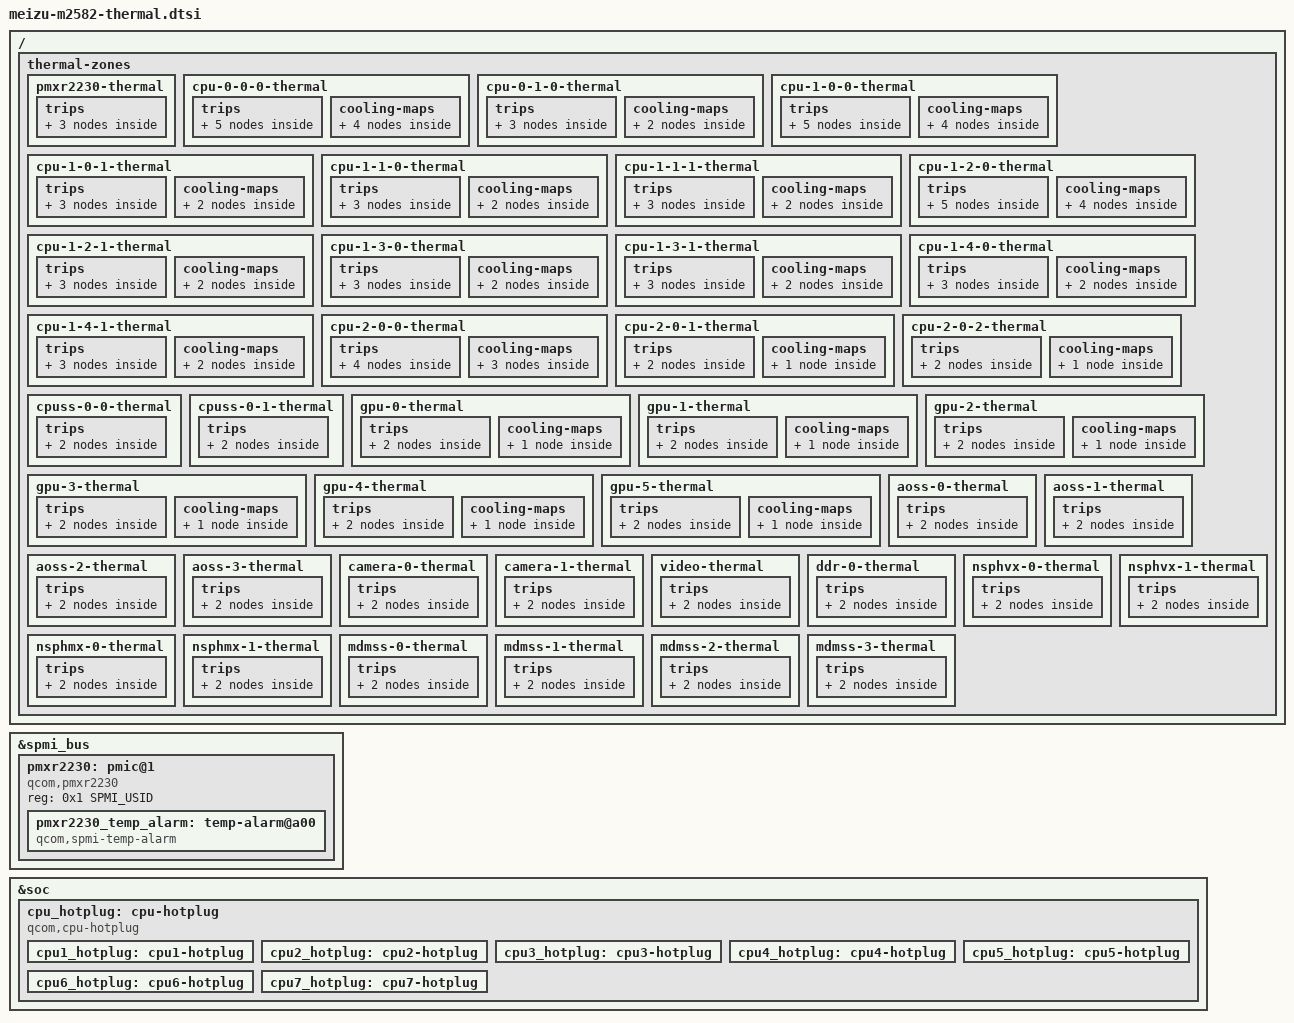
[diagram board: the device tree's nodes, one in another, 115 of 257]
// SPDX-License-Identifier: BSD-3-Clause
#include <dt-bindings/thermal/thermal.h>
/*
 * Meizu 22 (M2582) -- thermal zones.
 *
 * Two independent sensor families.  The TSENS zones are the ones with
 * actuators -- the three cpufreq cooling devices and the GPU's devfreq
 * cooling device:
 *
 *  - SoC TSENS (nodes in tuna.dtsi), which is uncalibrated on this part: the
 *    result register reports deci-Celsius and the vendor's tree claims no
 *    calibration cells, so the generic v2 path is what the phone itself runs.
 *    All 39 sensors are zones, as the vendor has them.
 *
 *  - The PMXR2230, which supplies the CPU rails and protects its own die in
 *    hardware: stage 2 and stage 3 shutdown are armed by default, so it cuts
 *    the rails with Linux out of the loop.  Its zone is a stage indicator
 *    rather than a thermometer, and it cannot drive a cooling device on this
 *    kernel -- see the note in that zone.
 *
 * Actuators: cpufreq-cpu0/-cpu4/-cpu7 for the clusters, devfreq-3d00000.gpu
 * for the GPU, and cpuN-hotplug for the emergency trips.  The board
 * thermistors are not modelled yet, so the vendor's skin-driven ladder has no
 * equivalent here.
 */
&spmi_bus {
	pmxr2230: pmic@1 {
		compatible = "qcom,pmxr2230", "qcom,spmi-pmic";
		reg = <0x1 SPMI_USID>;
		#address-cells = <1>;
		#size-cells = <0>;

		pmxr2230_temp_alarm: temp-alarm@a00 {
			compatible = "qcom,spmi-temp-alarm";
			reg = <0xa00>;
			interrupts = <0x1 0xa 0x0 IRQ_TYPE_EDGE_BOTH>;
			#thermal-sensor-cells = <0>;
		};
	};
};

/ {
	thermal-zones {
		pmxr2230-thermal {
			polling-delay-passive = <100>;

			thermal-sensors = <&pmxr2230_temp_alarm>;

			trips {
				pmxr2230_trip0: trip0 {
					temperature = <95000>;
					hysteresis = <0>;
					type = "passive";
				};

				pmxr2230_trip1: trip1 {
					temperature = <115000>;
					hysteresis = <0>;
					type = "hot";
				};

				pmxr2230_trip2: trip2 {
					temperature = <145000>;
					hysteresis = <0>;
					type = "critical";
				};
			};

			/*
			 * No cooling map: it cannot bind.  thermal_of.c matches a map
			 * to a trip through trip->priv, but qcom-spmi-temp-alarm stores
			 * its own trip index there (THERMAL_INT_TO_TRIP_PRIV, a core
			 * sanctioned encoding), so every lookup compares a trip node
			 * against a small integer.  Fixing that is a thermal core change.
			 * The zone is also not a thermometer: it reports DEFAULT_TEMP
			 * (37 C) until the PMIC enters a hardware stage.  Stage 2/3
			 * shutdown still protects the board on its own.
			 */
		};

		/*
		 * CPU sensors, all 17 of them, as the vendor models them.
		 *
		 *   tsens0  s1..s3 cpu-2-0-{0,1,2}   s4,s5 cpu-1-0-{0,1}
		 *           s6,s7 cpu-1-1-{0,1}      s0    aoss-0
		 *   tsens1  s1,s2 cpuss-0-{0,1}      s3,s4 cpu-1-2-{0,1}
		 *           s5,s6 cpu-1-3-{0,1}      s7,s8 cpu-1-4-{0,1}
		 *           s9    cpu-0-0-0          s10   cpu-0-1-0        s0 aoss-1
		 *
		 * The five cluster hotspots carry the graded ladder (85 C caps the
		 * clusters four OPPs down, 95 C may use the whole table).  The other
		 * twelve only carry the emergency trips: fourteen more copies of the
		 * ladder would give any single sensor the power to throttle the SoC.
		 *
		 * Emergency, per zone, following the vendor's zone-to-CPU mapping:
		 * 118 C offline that CPU, 120 C offline its policy peers, 125 C
		 * critical.  The cooling spec is <&cpuN_hotplug 0 1>, deliberately
		 * not the vendor's 1 1: step_wise releases to an instance's lower
		 * bound, so 1 1 latches the CPU offline for good.  Zones the vendor
		 * points at cpu0 use its policy sibling, which the kernel can
		 * actually offline.
		 */
		cpu-0-0-0-thermal {
			polling-delay-passive = <100>;
			thermal-sensors = <&tsens1 9>;
			trips {
				cpu_0_0_0_warm: trip-point0 {
					temperature = <85000>;
					hysteresis = <2000>;
					type = "passive";
				};
				cpu_0_0_0_alert: trip-point1 {
					temperature = <95000>;
					hysteresis = <2000>;
					type = "passive";
				};
				cpu_0_0_0_emerg: trip-point2 {
					temperature = <118000>;
					hysteresis = <8000>;
					type = "passive";
				};
				cpu_0_0_0_emerg2: trip-point3 {
					temperature = <120000>;
					hysteresis = <10000>;
					type = "passive";
				};
				cpu_0_0_0_crit: trip-point4 {
					temperature = <125000>;
					hysteresis = <1000>;
					type = "critical";
				};
			};
			cooling-maps {
				map-warm {
					trip = <&cpu_0_0_0_warm>;
					cooling-device = <&cpu0 0 4>, <&cpu4 0 4>, <&cpu7 0 4>;
				};
				map-hot {
					trip = <&cpu_0_0_0_alert>;
					cooling-device = <&cpu0 THERMAL_NO_LIMIT THERMAL_NO_LIMIT>,
							 <&cpu4 THERMAL_NO_LIMIT THERMAL_NO_LIMIT>,
							 <&cpu7 THERMAL_NO_LIMIT THERMAL_NO_LIMIT>;
				};
				map-emerg {
					trip = <&cpu_0_0_0_emerg>;
					cooling-device = <&cpu1_hotplug 0 1>;
				};
				map-emerg2 {
					trip = <&cpu_0_0_0_emerg2>;
					cooling-device = <&cpu2_hotplug 0 1>,
							 <&cpu3_hotplug 0 1>;
				};
			};
		};

		cpu-0-1-0-thermal {
			polling-delay-passive = <100>;
			thermal-sensors = <&tsens1 10>;
			trips {
				cpu_0_1_0_emerg: trip-point2 {
					temperature = <118000>;
					hysteresis = <8000>;
					type = "passive";
				};
				cpu_0_1_0_emerg2: trip-point3 {
					temperature = <120000>;
					hysteresis = <10000>;
					type = "passive";
				};
				cpu_0_1_0_crit: trip-point4 {
					temperature = <125000>;
					hysteresis = <1000>;
					type = "critical";
				};
			};
			cooling-maps {
				map-emerg {
					trip = <&cpu_0_1_0_emerg>;
					cooling-device = <&cpu1_hotplug 0 1>;
				};
				map-emerg2 {
					trip = <&cpu_0_1_0_emerg2>;
					cooling-device = <&cpu2_hotplug 0 1>,
							 <&cpu3_hotplug 0 1>;
				};
			};
		};

		cpu-1-0-0-thermal {
			polling-delay-passive = <100>;
			thermal-sensors = <&tsens0 4>;
			trips {
				cpu_1_0_0_warm: trip-point0 {
					temperature = <85000>;
					hysteresis = <2000>;
					type = "passive";
				};
				cpu_1_0_0_alert: trip-point1 {
					temperature = <95000>;
					hysteresis = <2000>;
					type = "passive";
				};
				cpu_1_0_0_emerg: trip-point2 {
					temperature = <118000>;
					hysteresis = <8000>;
					type = "passive";
				};
				cpu_1_0_0_emerg2: trip-point3 {
					temperature = <120000>;
					hysteresis = <10000>;
					type = "passive";
				};
				cpu_1_0_0_crit: trip-point4 {
					temperature = <125000>;
					hysteresis = <1000>;
					type = "critical";
				};
			};
			cooling-maps {
				map-warm {
					trip = <&cpu_1_0_0_warm>;
					cooling-device = <&cpu0 0 4>, <&cpu4 0 4>, <&cpu7 0 4>;
				};
				map-hot {
					trip = <&cpu_1_0_0_alert>;
					cooling-device = <&cpu0 THERMAL_NO_LIMIT THERMAL_NO_LIMIT>,
							 <&cpu4 THERMAL_NO_LIMIT THERMAL_NO_LIMIT>,
							 <&cpu7 THERMAL_NO_LIMIT THERMAL_NO_LIMIT>;
				};
				map-emerg {
					trip = <&cpu_1_0_0_emerg>;
					cooling-device = <&cpu5_hotplug 0 1>;
				};
				map-emerg2 {
					trip = <&cpu_1_0_0_emerg2>;
					cooling-device = <&cpu4_hotplug 0 1>,
							 <&cpu6_hotplug 0 1>;
				};
			};
		};

		cpu-1-0-1-thermal {
			polling-delay-passive = <100>;
			thermal-sensors = <&tsens0 5>;
			trips {
				cpu_1_0_1_emerg: trip-point2 {
					temperature = <118000>;
					hysteresis = <8000>;
					type = "passive";
				};
				cpu_1_0_1_emerg2: trip-point3 {
					temperature = <120000>;
					hysteresis = <10000>;
					type = "passive";
				};
				cpu_1_0_1_crit: trip-point4 {
					temperature = <125000>;
					hysteresis = <1000>;
					type = "critical";
				};
			};
			cooling-maps {
				map-emerg {
					trip = <&cpu_1_0_1_emerg>;
					cooling-device = <&cpu5_hotplug 0 1>;
				};
				map-emerg2 {
					trip = <&cpu_1_0_1_emerg2>;
					cooling-device = <&cpu4_hotplug 0 1>,
							 <&cpu6_hotplug 0 1>;
				};
			};
		};

		cpu-1-1-0-thermal {
			polling-delay-passive = <100>;
			thermal-sensors = <&tsens0 6>;
			trips {
				cpu_1_1_0_emerg: trip-point2 {
					temperature = <118000>;
					hysteresis = <8000>;
					type = "passive";
				};
				cpu_1_1_0_emerg2: trip-point3 {
					temperature = <120000>;
					hysteresis = <10000>;
					type = "passive";
				};
				cpu_1_1_0_crit: trip-point4 {
					temperature = <125000>;
					hysteresis = <1000>;
					type = "critical";
				};
			};
			cooling-maps {
				map-emerg {
					trip = <&cpu_1_1_0_emerg>;
					cooling-device = <&cpu6_hotplug 0 1>;
				};
				map-emerg2 {
					trip = <&cpu_1_1_0_emerg2>;
					cooling-device = <&cpu4_hotplug 0 1>,
							 <&cpu5_hotplug 0 1>;
				};
			};
		};

		cpu-1-1-1-thermal {
			polling-delay-passive = <100>;
			thermal-sensors = <&tsens0 7>;
			trips {
				cpu_1_1_1_emerg: trip-point2 {
					temperature = <118000>;
					hysteresis = <8000>;
					type = "passive";
				};
				cpu_1_1_1_emerg2: trip-point3 {
					temperature = <120000>;
					hysteresis = <10000>;
					type = "passive";
				};
				cpu_1_1_1_crit: trip-point4 {
					temperature = <125000>;
					hysteresis = <1000>;
					type = "critical";
				};
			};
			cooling-maps {
				map-emerg {
					trip = <&cpu_1_1_1_emerg>;
					cooling-device = <&cpu6_hotplug 0 1>;
				};
				map-emerg2 {
					trip = <&cpu_1_1_1_emerg2>;
					cooling-device = <&cpu4_hotplug 0 1>,
							 <&cpu5_hotplug 0 1>;
				};
			};
		};

		cpu-1-2-0-thermal {
			polling-delay-passive = <100>;
			thermal-sensors = <&tsens1 3>;
			trips {
				cpu_1_2_0_warm: trip-point0 {
					temperature = <85000>;
					hysteresis = <2000>;
					type = "passive";
				};
				cpu_1_2_0_alert: trip-point1 {
					temperature = <95000>;
					hysteresis = <2000>;
					type = "passive";
				};
				cpu_1_2_0_emerg: trip-point2 {
					temperature = <118000>;
					hysteresis = <8000>;
					type = "passive";
				};
				cpu_1_2_0_emerg2: trip-point3 {
					temperature = <120000>;
					hysteresis = <10000>;
					type = "passive";
				};
				cpu_1_2_0_crit: trip-point4 {
					temperature = <125000>;
					hysteresis = <1000>;
					type = "critical";
				};
			};
			cooling-maps {
				map-warm {
					trip = <&cpu_1_2_0_warm>;
					cooling-device = <&cpu0 0 4>, <&cpu4 0 4>, <&cpu7 0 4>;
				};
				map-hot {
					trip = <&cpu_1_2_0_alert>;
					cooling-device = <&cpu0 THERMAL_NO_LIMIT THERMAL_NO_LIMIT>,
							 <&cpu4 THERMAL_NO_LIMIT THERMAL_NO_LIMIT>,
							 <&cpu7 THERMAL_NO_LIMIT THERMAL_NO_LIMIT>;
				};
				map-emerg {
					trip = <&cpu_1_2_0_emerg>;
					cooling-device = <&cpu2_hotplug 0 1>;
				};
				map-emerg2 {
					trip = <&cpu_1_2_0_emerg2>;
					cooling-device = <&cpu1_hotplug 0 1>,
							 <&cpu3_hotplug 0 1>;
				};
			};
		};

		cpu-1-2-1-thermal {
			polling-delay-passive = <100>;
			thermal-sensors = <&tsens1 4>;
			trips {
				cpu_1_2_1_emerg: trip-point2 {
					temperature = <118000>;
					hysteresis = <8000>;
					type = "passive";
				};
				cpu_1_2_1_emerg2: trip-point3 {
					temperature = <120000>;
					hysteresis = <10000>;
					type = "passive";
				};
				cpu_1_2_1_crit: trip-point4 {
					temperature = <125000>;
					hysteresis = <1000>;
					type = "critical";
				};
			};
			cooling-maps {
				map-emerg {
					trip = <&cpu_1_2_1_emerg>;
					cooling-device = <&cpu2_hotplug 0 1>;
				};
				map-emerg2 {
					trip = <&cpu_1_2_1_emerg2>;
					cooling-device = <&cpu1_hotplug 0 1>,
							 <&cpu3_hotplug 0 1>;
				};
			};
		};

		cpu-1-3-0-thermal {
			polling-delay-passive = <100>;
			thermal-sensors = <&tsens1 5>;
			trips {
				cpu_1_3_0_emerg: trip-point2 {
					temperature = <118000>;
					hysteresis = <8000>;
					type = "passive";
				};
				cpu_1_3_0_emerg2: trip-point3 {
					temperature = <120000>;
					hysteresis = <10000>;
					type = "passive";
				};
				cpu_1_3_0_crit: trip-point4 {
					temperature = <125000>;
					hysteresis = <1000>;
					type = "critical";
				};
			};
			cooling-maps {
				map-emerg {
					trip = <&cpu_1_3_0_emerg>;
					cooling-device = <&cpu3_hotplug 0 1>;
				};
				map-emerg2 {
					trip = <&cpu_1_3_0_emerg2>;
					cooling-device = <&cpu1_hotplug 0 1>,
							 <&cpu2_hotplug 0 1>;
				};
			};
		};

		cpu-1-3-1-thermal {
			polling-delay-passive = <100>;
			thermal-sensors = <&tsens1 6>;
			trips {
				cpu_1_3_1_emerg: trip-point2 {
					temperature = <118000>;
					hysteresis = <8000>;
					type = "passive";
				};
				cpu_1_3_1_emerg2: trip-point3 {
					temperature = <120000>;
					hysteresis = <10000>;
					type = "passive";
				};
				cpu_1_3_1_crit: trip-point4 {
					temperature = <125000>;
					hysteresis = <1000>;
					type = "critical";
				};
			};
			cooling-maps {
				map-emerg {
					trip = <&cpu_1_3_1_emerg>;
					cooling-device = <&cpu3_hotplug 0 1>;
				};
				map-emerg2 {
					trip = <&cpu_1_3_1_emerg2>;
					cooling-device = <&cpu1_hotplug 0 1>,
							 <&cpu2_hotplug 0 1>;
				};
			};
		};

		cpu-1-4-0-thermal {
			polling-delay-passive = <100>;
			thermal-sensors = <&tsens1 7>;
			trips {
				cpu_1_4_0_emerg: trip-point2 {
					temperature = <118000>;
					hysteresis = <8000>;
					type = "passive";
				};
				cpu_1_4_0_emerg2: trip-point3 {
					temperature = <120000>;
					hysteresis = <10000>;
					type = "passive";
				};
				cpu_1_4_0_crit: trip-point4 {
					temperature = <125000>;
					hysteresis = <1000>;
					type = "critical";
				};
			};
			cooling-maps {
				map-emerg {
					trip = <&cpu_1_4_0_emerg>;
					cooling-device = <&cpu4_hotplug 0 1>;
				};
				map-emerg2 {
					trip = <&cpu_1_4_0_emerg2>;
					cooling-device = <&cpu5_hotplug 0 1>,
							 <&cpu6_hotplug 0 1>;
				};
			};
		};

		cpu-1-4-1-thermal {
			polling-delay-passive = <100>;
			thermal-sensors = <&tsens1 8>;
			trips {
				cpu_1_4_1_emerg: trip-point2 {
					temperature = <118000>;
					hysteresis = <8000>;
					type = "passive";
				};
				cpu_1_4_1_emerg2: trip-point3 {
					temperature = <120000>;
					hysteresis = <10000>;
					type = "passive";
				};
				cpu_1_4_1_crit: trip-point4 {
					temperature = <125000>;
					hysteresis = <1000>;
					type = "critical";
				};
			};
			cooling-maps {
				map-emerg {
					trip = <&cpu_1_4_1_emerg>;
					cooling-device = <&cpu4_hotplug 0 1>;
				};
				map-emerg2 {
					trip = <&cpu_1_4_1_emerg2>;
					cooling-device = <&cpu5_hotplug 0 1>,
							 <&cpu6_hotplug 0 1>;
				};
			};
		};

		cpu-2-0-0-thermal {
			polling-delay-passive = <100>;
			thermal-sensors = <&tsens0 1>;
			trips {
				cpu_2_0_0_warm: trip-point0 {
					temperature = <85000>;
					hysteresis = <2000>;
					type = "passive";
				};
				cpu_2_0_0_alert: trip-point1 {
					temperature = <95000>;
					hysteresis = <2000>;
					type = "passive";
				};
				cpu_2_0_0_emerg: trip-point2 {
					temperature = <118000>;
					hysteresis = <8000>;
					type = "passive";
				};
				cpu_2_0_0_crit: trip-point4 {
					temperature = <125000>;
					hysteresis = <1000>;
					type = "critical";
				};
			};
			cooling-maps {
				map-warm {
					trip = <&cpu_2_0_0_warm>;
					cooling-device = <&cpu0 0 4>, <&cpu4 0 4>, <&cpu7 0 4>;
				};
				map-hot {
					trip = <&cpu_2_0_0_alert>;
					cooling-device = <&cpu0 THERMAL_NO_LIMIT THERMAL_NO_LIMIT>,
							 <&cpu4 THERMAL_NO_LIMIT THERMAL_NO_LIMIT>,
							 <&cpu7 THERMAL_NO_LIMIT THERMAL_NO_LIMIT>;
				};
				map-emerg {
					trip = <&cpu_2_0_0_emerg>;
					cooling-device = <&cpu7_hotplug 0 1>;
				};
			};
		};

		cpu-2-0-1-thermal {
			polling-delay-passive = <100>;
			thermal-sensors = <&tsens0 2>;
			trips {
				cpu_2_0_1_emerg: trip-point2 {
					temperature = <118000>;
					hysteresis = <8000>;
					type = "passive";
				};
				cpu_2_0_1_crit: trip-point4 {
					temperature = <125000>;
					hysteresis = <1000>;
					type = "critical";
				};
			};
			cooling-maps {
				map-emerg {
					trip = <&cpu_2_0_1_emerg>;
					cooling-device = <&cpu7_hotplug 0 1>;
				};
			};
		};

		cpu-2-0-2-thermal {
			polling-delay-passive = <100>;
			thermal-sensors = <&tsens0 3>;
			trips {
				cpu_2_0_2_emerg: trip-point2 {
					temperature = <118000>;
					hysteresis = <8000>;
					type = "passive";
				};
				cpu_2_0_2_crit: trip-point4 {
					temperature = <125000>;
					hysteresis = <1000>;
					type = "critical";
				};
			};
			cooling-maps {
				map-emerg {
					trip = <&cpu_2_0_2_emerg>;
					cooling-device = <&cpu7_hotplug 0 1>;
				};
			};
		};

		cpuss-0-0-thermal {
			polling-delay-passive = <100>;
			thermal-sensors = <&tsens1 1>;
			trips {
				cpuss_0_0_alert: trip-point0 {
					temperature = <105000>;
					hysteresis = <5000>;
					type = "passive";
				};
				cpuss_0_0_crit: trip-point4 {
					temperature = <125000>;
					hysteresis = <1000>;
					type = "critical";
				};
			};
		};

		cpuss-0-1-thermal {
			polling-delay-passive = <100>;
			thermal-sensors = <&tsens1 2>;
			trips {
				cpuss_0_1_alert: trip-point0 {
					temperature = <105000>;
					hysteresis = <5000>;
					type = "passive";
				};
				cpuss_0_1_crit: trip-point4 {
					temperature = <125000>;
					hysteresis = <1000>;
					type = "critical";
				};
			};
		};

		/*
		 * GPU: six sensors (tsens2 s5..s10), as the vendor has them.  The
		 * vendor's own die controller runs off gpu-2, so a single zone was
		 * probably not the hot corner.  All six share one cooling device and
		 * __thermal_cdev_update() keeps the deepest request.
		 *
		 * 105 C with the whole OPP table, not the vendor's 0..2: it leaves the
		 * deep cap to its userspace policy at 45.5 C skin, and we have none.
		 */

		gpu-0-thermal {
			polling-delay-passive = <10>;
			thermal-sensors = <&tsens2 5>;
			trips {
				gpu_0_alert: trip-point0 {
					temperature = <105000>;
					hysteresis = <5000>;
					type = "passive";
				};
				gpu_0_crit: trip-point1 {
					temperature = <125000>;
					hysteresis = <1000>;
					type = "critical";
				};
			};
			cooling-maps {
				map-gpu {
					trip = <&gpu_0_alert>;
					cooling-device = <&gpu 0 10>;
				};
			};
		};

		gpu-1-thermal {
			polling-delay-passive = <10>;
			thermal-sensors = <&tsens2 6>;
			trips {
				gpu_1_alert: trip-point0 {
					temperature = <105000>;
					hysteresis = <5000>;
					type = "passive";
				};
				gpu_1_crit: trip-point1 {
					temperature = <125000>;
					hysteresis = <1000>;
					type = "critical";
				};
			};
			cooling-maps {
				map-gpu {
					trip = <&gpu_1_alert>;
					cooling-device = <&gpu 0 10>;
				};
			};
		};

		gpu-2-thermal {
			polling-delay-passive = <10>;
			thermal-sensors = <&tsens2 7>;
			trips {
				gpu_2_alert: trip-point0 {
					temperature = <105000>;
					hysteresis = <5000>;
					type = "passive";
				};
				gpu_2_crit: trip-point1 {
					temperature = <125000>;
					hysteresis = <1000>;
					type = "critical";
				};
			};
			cooling-maps {
				map-gpu {
					trip = <&gpu_2_alert>;
					cooling-device = <&gpu 0 10>;
				};
			};
		};

		gpu-3-thermal {
			polling-delay-passive = <10>;
			thermal-sensors = <&tsens2 8>;
			trips {
				gpu_3_alert: trip-point0 {
					temperature = <105000>;
					hysteresis = <5000>;
					type = "passive";
				};
				gpu_3_crit: trip-point1 {
					temperature = <125000>;
					hysteresis = <1000>;
					type = "critical";
				};
			};
			cooling-maps {
				map-gpu {
					trip = <&gpu_3_alert>;
					cooling-device = <&gpu 0 10>;
				};
			};
		};

		gpu-4-thermal {
			polling-delay-passive = <10>;
			thermal-sensors = <&tsens2 9>;
			trips {
				gpu_4_alert: trip-point0 {
					temperature = <105000>;
					hysteresis = <5000>;
					type = "passive";
				};
				gpu_4_crit: trip-point1 {
					temperature = <125000>;
					hysteresis = <1000>;
					type = "critical";
				};
			};
			cooling-maps {
				map-gpu {
					trip = <&gpu_4_alert>;
					cooling-device = <&gpu 0 10>;
				};
			};
		};

		gpu-5-thermal {
			polling-delay-passive = <10>;
			thermal-sensors = <&tsens2 10>;
			trips {
				gpu_5_alert: trip-point0 {
					temperature = <105000>;
					hysteresis = <5000>;
					type = "passive";
				};
				gpu_5_crit: trip-point1 {
					temperature = <125000>;
					hysteresis = <1000>;
					type = "critical";
				};
			};
			cooling-maps {
				map-gpu {
					trip = <&gpu_5_alert>;
					cooling-device = <&gpu 0 10>;
				};
			};
		};
		/*
		 * The remaining TSENS sensors: always-on island, camera ISP, Venus
		 * video, DDR controller, the two NSP clusters and the modem
		 * subsystem.
		 *
		 * Monitoring only.  None of these has an actuator in mainline --
		 * the vendor drives DDR DVFS and the NSP clocks from here -- so
		 * they carry no cooling map and the PMIC's stage 2/3 shutdown is
		 * their only backstop.
		 */
			/* always-on island */
		aoss-0-thermal {
			polling-delay-passive = <100>;
			thermal-sensors = <&tsens0 0>;
			trips {
				aoss_0_alert: trip-point0 {
					temperature = <105000>;
					hysteresis = <5000>;
					type = "passive";
				};
				aoss_0_hot: trip-point1 {
					temperature = <125000>;
					hysteresis = <0>;
					type = "hot";
				};
			};
		};

		aoss-1-thermal {
			polling-delay-passive = <100>;
			thermal-sensors = <&tsens1 0>;
			trips {
				aoss_1_alert: trip-point0 {
					temperature = <105000>;
					hysteresis = <5000>;
					type = "passive";
				};
				aoss_1_hot: trip-point1 {
					temperature = <125000>;
					hysteresis = <0>;
					type = "hot";
				};
			};
		};

		aoss-2-thermal {
			polling-delay-passive = <100>;
			thermal-sensors = <&tsens2 0>;
			trips {
				aoss_2_alert: trip-point0 {
					temperature = <105000>;
					hysteresis = <5000>;
					type = "passive";
				};
				aoss_2_hot: trip-point1 {
					temperature = <125000>;
					hysteresis = <0>;
					type = "hot";
				};
			};
		};

		aoss-3-thermal {
			polling-delay-passive = <100>;
			thermal-sensors = <&tsens3 0>;
			trips {
				aoss_3_alert: trip-point0 {
					temperature = <105000>;
					hysteresis = <5000>;
					type = "passive";
				};
				aoss_3_hot: trip-point1 {
					temperature = <125000>;
					hysteresis = <0>;
					type = "hot";
				};
			};
		};

			/* ISP / camera */
		camera-0-thermal {
			polling-delay-passive = <100>;
			thermal-sensors = <&tsens2 1>;
			trips {
				camera_0_alert: trip-point0 {
					temperature = <105000>;
					hysteresis = <5000>;
					type = "passive";
				};
				camera_0_hot: trip-point1 {
					temperature = <125000>;
					hysteresis = <0>;
					type = "hot";
				};
			};
		};

		camera-1-thermal {
			polling-delay-passive = <100>;
			thermal-sensors = <&tsens2 2>;
			trips {
				camera_1_alert: trip-point0 {
					temperature = <105000>;
					hysteresis = <5000>;
					type = "passive";
				};
				camera_1_hot: trip-point1 {
					temperature = <125000>;
					hysteresis = <0>;
					type = "hot";
				};
			};
		};

			/* Venus video */
		video-thermal {
			polling-delay-passive = <100>;
			thermal-sensors = <&tsens2 3>;
			trips {
				video_alert: trip-point0 {
					temperature = <105000>;
					hysteresis = <5000>;
					type = "passive";
				};
				video_hot: trip-point1 {
					temperature = <125000>;
					hysteresis = <0>;
					type = "hot";
				};
			};
		};

			/* DDR / memory controller */
		ddr-0-thermal {
			polling-delay-passive = <100>;
			thermal-sensors = <&tsens2 4>;
			trips {
				ddr_0_alert: trip-point0 {
					temperature = <105000>;
					hysteresis = <5000>;
					type = "passive";
				};
				ddr_0_hot: trip-point1 {
					temperature = <125000>;
					hysteresis = <0>;
					type = "hot";
				};
			};
		};

			/* Hexagon NSP (vector) */
		nsphvx-0-thermal {
			polling-delay-passive = <100>;
			thermal-sensors = <&tsens2 11>;
			trips {
				nsphvx_0_alert: trip-point0 {
					temperature = <105000>;
					hysteresis = <5000>;
					type = "passive";
				};
				nsphvx_0_hot: trip-point1 {
					temperature = <125000>;
					hysteresis = <0>;
					type = "hot";
				};
			};
		};

		nsphvx-1-thermal {
			polling-delay-passive = <100>;
			thermal-sensors = <&tsens2 12>;
			trips {
				nsphvx_1_alert: trip-point0 {
					temperature = <105000>;
					hysteresis = <5000>;
					type = "passive";
				};
				nsphvx_1_hot: trip-point1 {
					temperature = <125000>;
					hysteresis = <0>;
					type = "hot";
				};
			};
		};

			/* Hexagon NSP (matrix) */
		nsphmx-0-thermal {
			polling-delay-passive = <100>;
			thermal-sensors = <&tsens2 13>;
			trips {
				nsphmx_0_alert: trip-point0 {
					temperature = <105000>;
					hysteresis = <5000>;
					type = "passive";
				};
				nsphmx_0_hot: trip-point1 {
					temperature = <125000>;
					hysteresis = <0>;
					type = "hot";
				};
			};
		};

		nsphmx-1-thermal {
			polling-delay-passive = <100>;
			thermal-sensors = <&tsens2 14>;
			trips {
				nsphmx_1_alert: trip-point0 {
					temperature = <105000>;
					hysteresis = <5000>;
					type = "passive";
				};
				nsphmx_1_hot: trip-point1 {
					temperature = <125000>;
					hysteresis = <0>;
					type = "hot";
				};
			};
		};

			/* modem subsystem */
		mdmss-0-thermal {
			polling-delay-passive = <100>;
			thermal-sensors = <&tsens3 1>;
			trips {
				mdmss_0_alert: trip-point0 {
					temperature = <105000>;
					hysteresis = <5000>;
					type = "passive";
				};
				mdmss_0_hot: trip-point1 {
					temperature = <125000>;
					hysteresis = <0>;
					type = "hot";
				};
			};
		};

		mdmss-1-thermal {
			polling-delay-passive = <100>;
			thermal-sensors = <&tsens3 2>;
			trips {
				mdmss_1_alert: trip-point0 {
					temperature = <105000>;
					hysteresis = <5000>;
					type = "passive";
				};
				mdmss_1_hot: trip-point1 {
					temperature = <125000>;
					hysteresis = <0>;
					type = "hot";
				};
			};
		};

		mdmss-2-thermal {
			polling-delay-passive = <100>;
			thermal-sensors = <&tsens3 3>;
			trips {
				mdmss_2_alert: trip-point0 {
					temperature = <105000>;
					hysteresis = <5000>;
					type = "passive";
				};
				mdmss_2_hot: trip-point1 {
					temperature = <125000>;
					hysteresis = <0>;
					type = "hot";
				};
			};
		};

		mdmss-3-thermal {
			polling-delay-passive = <100>;
			thermal-sensors = <&tsens3 4>;
			trips {
				mdmss_3_alert: trip-point0 {
					temperature = <105000>;
					hysteresis = <5000>;
					type = "passive";
				};
				mdmss_3_hot: trip-point1 {
					temperature = <125000>;
					hysteresis = <0>;
					type = "hot";
				};
			};
		};

	};
};

/*
 * Hotplug cooling devices for the emergency trips above.
 *
 * One device per CPU, state 1 offlines it.  cpu0 is deliberately absent: the
 * kernel refuses to offline it, so a device for it could only ever fail.
 */
&soc {
	cpu_hotplug: cpu-hotplug {
		compatible = "qcom,cpu-hotplug";

		cpu1_hotplug: cpu1-hotplug {
			qcom,cpu = <&cpu1>;
			qcom,cdev-alias = "cpu1-hotplug";
			#cooling-cells = <2>;
		};

		cpu2_hotplug: cpu2-hotplug {
			qcom,cpu = <&cpu2>;
			qcom,cdev-alias = "cpu2-hotplug";
			#cooling-cells = <2>;
		};

		cpu3_hotplug: cpu3-hotplug {
			qcom,cpu = <&cpu3>;
			qcom,cdev-alias = "cpu3-hotplug";
			#cooling-cells = <2>;
		};

		cpu4_hotplug: cpu4-hotplug {
			qcom,cpu = <&cpu4>;
			qcom,cdev-alias = "cpu4-hotplug";
			#cooling-cells = <2>;
		};

		cpu5_hotplug: cpu5-hotplug {
			qcom,cpu = <&cpu5>;
			qcom,cdev-alias = "cpu5-hotplug";
			#cooling-cells = <2>;
		};

		cpu6_hotplug: cpu6-hotplug {
			qcom,cpu = <&cpu6>;
			qcom,cdev-alias = "cpu6-hotplug";
			#cooling-cells = <2>;
		};

		cpu7_hotplug: cpu7-hotplug {
			qcom,cpu = <&cpu7>;
			qcom,cdev-alias = "cpu7-hotplug";
			#cooling-cells = <2>;
		};
	};
};
